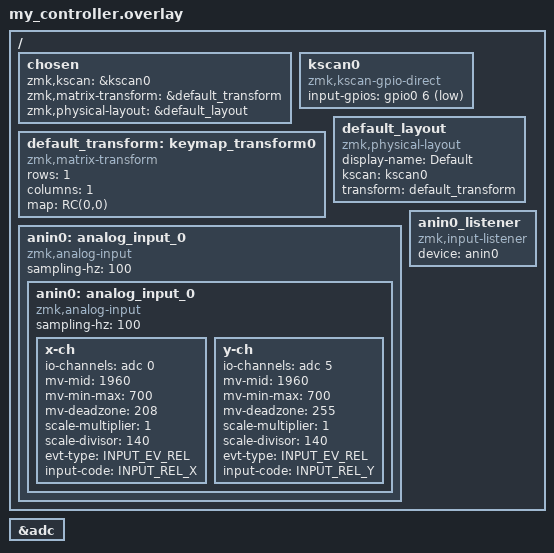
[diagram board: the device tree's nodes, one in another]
#include <dt-bindings/zmk/matrix_transform.h>
#include <zephyr/dt-bindings/gpio/gpio.h>
#include <zephyr/dt-bindings/input/input-event-codes.h>

/ {
    chosen {
        zmk,kscan = &kscan0;
        zmk,matrix-transform = &default_transform;
        zmk,physical-layout = &default_layout;
    };

    kscan0: kscan0 {
        compatible = "zmk,kscan-gpio-direct";
        input-gpios = <&gpio0 6 (GPIO_ACTIVE_LOW | GPIO_PULL_UP)>;
    };

    default_transform: keymap_transform0 {
        compatible = "zmk,matrix-transform";
        rows = <1>;
        columns = <1>;
        map = <RC(0,0)>;
    };

    default_layout: default_layout {
        compatible = "zmk,physical-layout";
        display-name = "Default";
        kscan = <&kscan0>;
        transform = <&default_transform>;
    };

    anin0: analog_input_0 {
        compatible = "zmk,analog-input";
        sampling-hz = <100>;

      anin0: analog_input_0 {
    compatible = "zmk,analog-input";
    sampling-hz = <100>;

    x-ch {
        io-channels = <&adc 0>;
        mv-mid = <1960>;
        mv-min-max = <700>;
        mv-deadzone = <208>;
        scale-multiplier = <1>;
        scale-divisor = <140>;
        evt-type = <INPUT_EV_REL>;
        input-code = <INPUT_REL_X>;
    };

    y-ch {
        io-channels = <&adc 5>;
        mv-mid = <1960>;
        mv-min-max = <700>;
        mv-deadzone = <255>;
        scale-multiplier = <1>;
        scale-divisor = <140>;
        evt-type = <INPUT_EV_REL>;
        input-code = <INPUT_REL_Y>;
    };
};


    };

    anin0_listener: anin0_listener {
        compatible = "zmk,input-listener";
        device = <&anin0>;
    };
};

&adc {
    status = "okay";
};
